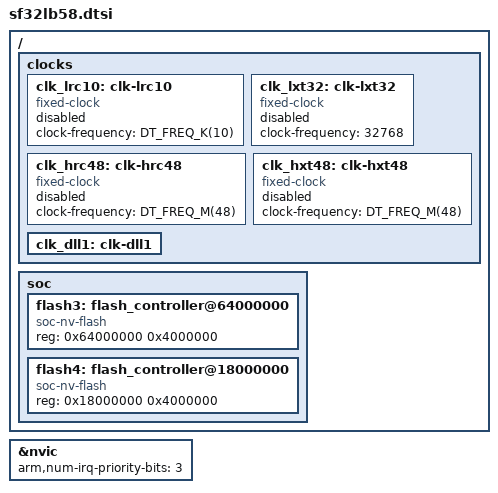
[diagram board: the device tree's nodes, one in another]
/*
 * Copyright (c) 2025 Qingdao IotPi Ltd.
 *
 * SPDX-License-Identifier: Apache-2.0
 */

#include <arm/armv8-m.dtsi>
#include <freq.h>
#include <mem.h>

/ {
    clocks {
        clk_lrc10: clk-lrc10 {
            compatible = "fixed-clock";
            #clock-cells = <0>;
            clock-frequency = <DT_FREQ_K(10)>;
            status = "disabled";
        };

        clk_lxt32: clk-lxt32 {
            compatible = "fixed-clock";
            #clock-cells = <0>;
            clock-frequency = <32768>;
            status = "disabled";
        };

        clk_hrc48: clk-hrc48 {
            compatible = "fixed-clock";
            #clock-cells = <0>;
            clock-frequency = <DT_FREQ_M(48)>;
            status = "disabled";
        };

        clk_hxt48: clk-hxt48 {
            compatible = "fixed-clock";
            #clock-cells = <0>;
            clock-frequency = <DT_FREQ_M(48)>;
            status = "disabled";
        };

        clk_dll1: clk-dll1 {
        };
    };

    soc {
        flash3: flash_controller@64000000 {
            compatible = "soc-nv-flash";
            reg = <0x64000000 0x4000000>;
        };

        flash4: flash_controller@18000000 {
            compatible = "soc-nv-flash";
            reg = <0x18000000 0x4000000>;
        };
    };
};

&nvic {
	arm,num-irq-priority-bits = <3>;
};
